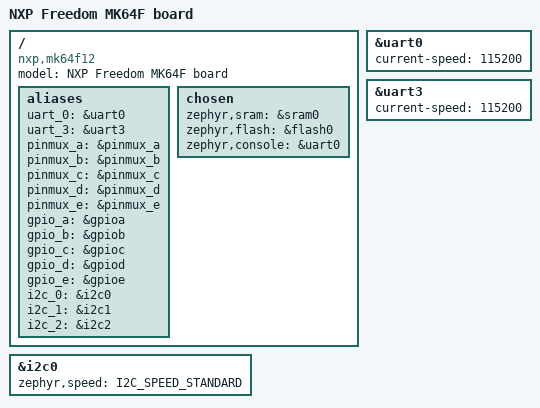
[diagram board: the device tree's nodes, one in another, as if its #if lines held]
/dts-v1/;

#include <nxp/nxp_k6x.dtsi>
#include <i2c.h>

/ {
	model = "NXP Freedom MK64F board";
	compatible = "nxp,mk64f12", "nxp,k64f", "nxp,k6x";

	aliases {
		uart_0 = &uart0;
		uart_3 = &uart3;
		pinmux_a = &pinmux_a;
		pinmux_b = &pinmux_b;
		pinmux_c = &pinmux_c;
		pinmux_d = &pinmux_d;
		pinmux_e = &pinmux_e;
		gpio_a = &gpioa;
		gpio_b = &gpiob;
		gpio_c = &gpioc;
		gpio_d = &gpiod;
		gpio_e = &gpioe;
		i2c_0 = &i2c0;
		i2c_1 = &i2c1;
		i2c_2 = &i2c2;
	};

	chosen {
		zephyr,sram = &sram0;
		zephyr,flash = &flash0;
		zephyr,console = &uart0;
	};
};

&i2c0 {
	status = "ok";
	zephyr,speed = <I2C_SPEED_STANDARD>;
};

&uart0 {
	status = "ok";
	current-speed = <115200>;
};

#ifdef CONFIG_BLUETOOTH
&uart3 {
	status = "ok";
	current-speed = <115200>;
};
#endif
